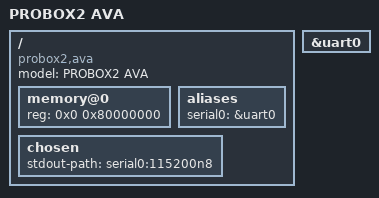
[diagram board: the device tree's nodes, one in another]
/*
 * Copyright (c) 2017 Andreas Färber
 *
 * SPDX-License-Identifier: (GPL-2.0+ OR MIT)
 */

/dts-v1/;

#include "rtd1295.dtsi"

/ {
	compatible = "probox2,ava", "realtek,rtd1295";
	model = "PROBOX2 AVA";

	memory@0 {
		device_type = "memory";
		reg = <0x0 0x80000000>;
	};

	aliases {
		serial0 = &uart0;
	};

	chosen {
		stdout-path = "serial0:115200n8";
	};
};

&uart0 {
	status = "okay";
};
